# nrf7120_enga_application register map
Vendor: Nordic Semiconductor; Series: nrf71; File version: 1
CPU: CM33 r0p4, little endian, MPU, FPU, 3 interrupt priority bits, 270 interrupts, 4 SAU regions
Registers are 32-bit, read-write, reset 0x0 unless marked. A register's access mark holds for its fields unless they carry their own. Offsets are from the block's base; [hi:lo] are bit positions; lines under a group give offsets from that group; 'fields as' and 'values as' point back to an identical list.

## GLOBAL_RESET_NS — Reset control 0
Base 0x4010E000; alternate view of GLOBAL_CLOCK_NS
Same registers: GLOBAL_RESET_S 0x5010E000 (alternate view of GLOBAL_CLOCK_S)
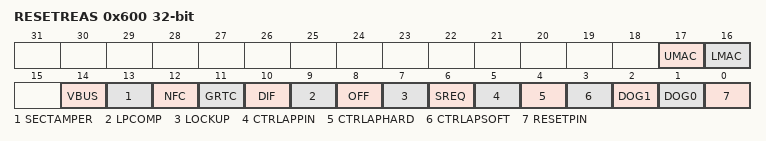
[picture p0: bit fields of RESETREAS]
0x600 RESETREAS — Reset reason
  [all] fields
    0=NotDetected; 1=Detected
  [17] UMAC — Reset from Wi-Fi UMAC watchdog
  [16] LMAC — Reset from Wi-Fi LMAC watchdog
  [14] VBUS — Reset after wakeup from System OFF mode due to VBUS rising into valid range
  [13] SECTAMPER — Reset due to illegal tampering of the device
  [12] NFC — Reset after wakeup from System OFF mode due to NFC field being detected
  [11] GRTC — Reset due to wakeup from GRTC
  [10] DIF — Reset triggered by Debug Interface
  [9] LPCOMP — Reset due to wakeup from System OFF mode when wakeup is triggered by ANADETECT signal from LPCOMP
  [8] OFF — Reset due to wakeup from System OFF mode when wakeup is triggered by DETECT signal from GPIO
  [7] LOCKUP — Reset from CPU lockup detected
  [6] SREQ — Reset from soft reset detected
  [5] CTRLAPPIN — Reset due to CTRL-AP pin reset
  [4] CTRLAPHARD — Reset due to CTRL-AP hard reset
  [3] CTRLAPSOFT — Soft reset from CTRL-AP detected
  [2] DOG1 — Reset from watchdog timer 1 detected
  [1] DOG0 — Reset from watchdog timer 0 detected
  [0] RESETPIN — Reset from pin reset detected

## GLOBAL_GLITCHDET_S — Voltage glitch detectors
Base 0x50111000
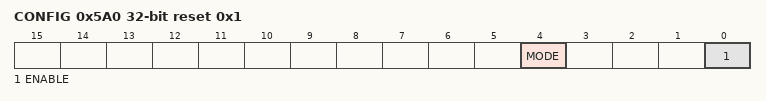
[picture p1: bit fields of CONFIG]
0x5A0 CONFIG reset 0x1 — Configuration for glitch detector
  [4] MODE — Glitch detector mode
    0=High pass filter mode; 1=Cap divider mode
  [0] ENABLE — Enable glitch detector
    0=Disable glitch detector; 1=Enable glitch detector

## GLOBAL_OSCILLATORS_NS — Oscillator control 0
Base 0x40120000
Same registers: GLOBAL_OSCILLATORS_S 0x50120000
0x800 PLL group — Oscillator control
  0x00 FREQ reset 0x4 — Set speed of MCU power domain, including CPU
    [2:0] FREQ — Select CPU speed
      0=CK256M (256 MHz); 2=CK128M (128 MHz); 4=CK64M (64 MHz); 6=CK43M (42.667 MHz)
  0x04 CURRENTFREQ ro reset 0x4 — Current speed of MCU power domain, including CPU
    [2:0] CURRENTFREQ — Select CPU speed
      values as PLL.FREQ.FREQ

## GLOBAL_REGULATORS_NS — Voltage regulators 0
Base 0x40120000; alternate view of GLOBAL_OSCILLATORS_NS
Same registers: GLOBAL_REGULATORS_S 0x50120000 (alternate view of GLOBAL_OSCILLATORS_S)
0x500 SYSTEMOFF wo
  [0] SYSTEMOFF — Enable System OFF mode
    1=Enter (Enable System OFF mode)

## GLOBAL_VREGUSB_NS — VREGUSB peripheral 0
Base 0x40121000
Same registers: GLOBAL_VREGUSB_S 0x50121000
0x00 TASKS_START wo — Request power up of USB PM
  [0] TASKS_START
    1=Trigger task
0x04 TASKS_STOP wo — Stop requesting power up of USB PM
  [0] TASKS_STOP
    1=Trigger task
0x104 EVENTS_VBUSDETECTED — VBUS detected
  [0] EVENTS_VBUSDETECTED
    0=NotGenerated (Event not generated); 1=Generated (Event generated)
0x108 EVENTS_SETTLED0V8 — 0V8 settled
  [0] EVENTS_SETTLED0V8
    values as EVENTS_VBUSDETECTED.EVENTS_VBUSDETECTED
0x10C EVENTS_SETTLED3V3 — 3V3 settled
  [0] EVENTS_SETTLED3V3
    values as EVENTS_VBUSDETECTED.EVENTS_VBUSDETECTED
0x110 EVENTS_VBUSREMOVED — VBUS removed
  [0] EVENTS_VBUSREMOVED
    values as EVENTS_VBUSDETECTED.EVENTS_VBUSDETECTED
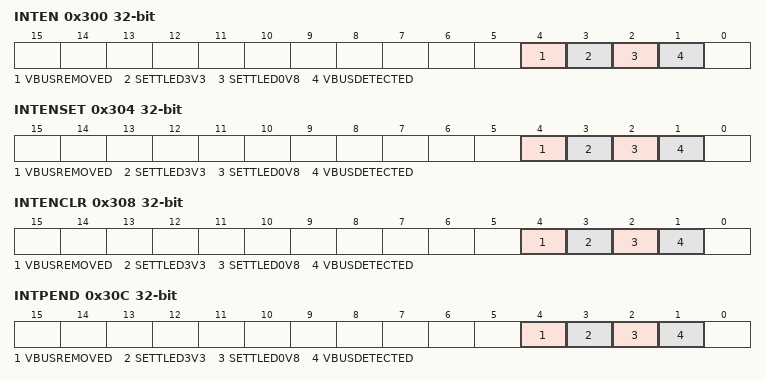
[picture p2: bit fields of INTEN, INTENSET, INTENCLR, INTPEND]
0x300 INTEN — Enable or disable interrupt
  [all] fields
    0=Disabled; 1=Enabled
  [4] VBUSREMOVED — Enable or disable interrupt for event VBUSREMOVED
  [3] SETTLED3V3 — Enable or disable interrupt for event SETTLED3V3
  [2] SETTLED0V8 — Enable or disable interrupt for event SETTLED0V8
  [1] VBUSDETECTED — Enable or disable interrupt for event VBUSDETECTED
0x304 INTENSET — Enable interrupt
  [all] fields
    on read: 0=Disabled (Read: Disabled); 1=Enabled (Read: Enabled) | on write: 1=Set (Enable)
  [4] VBUSREMOVED — Write '1' to enable interrupt for event VBUSREMOVED
  [3] SETTLED3V3 — Write '1' to enable interrupt for event SETTLED3V3
  [2] SETTLED0V8 — Write '1' to enable interrupt for event SETTLED0V8
  [1] VBUSDETECTED — Write '1' to enable interrupt for event VBUSDETECTED
0x308 INTENCLR — Disable interrupt
  [all] fields
    on read: 0=Disabled (Read: Disabled); 1=Enabled (Read: Enabled) | on write: 1=Clear (Disable)
  [4] VBUSREMOVED — Write '1' to disable interrupt for event VBUSREMOVED
  [3] SETTLED3V3 — Write '1' to disable interrupt for event SETTLED3V3
  [2] SETTLED0V8 — Write '1' to disable interrupt for event SETTLED0V8
  [1] VBUSDETECTED — Write '1' to disable interrupt for event VBUSDETECTED
0x30C INTPEND ro — Pending interrupts
  [all] fields
    on read: 0=NotPending (Read: Not pending); 1=Pending (Read: Pending)
  [4] VBUSREMOVED — Read pending status of interrupt for event VBUSREMOVED
  [3] SETTLED3V3 — Read pending status of interrupt for event SETTLED3V3
  [2] SETTLED0V8 — Read pending status of interrupt for event SETTLED0V8
  [1] VBUSDETECTED — Read pending status of interrupt for event VBUSDETECTED
